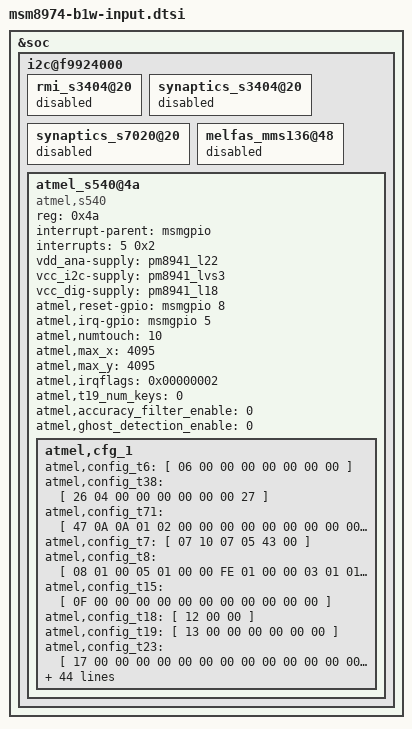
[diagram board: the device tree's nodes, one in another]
/* Copyright (c) 2012, Code Aurora Forum. All rights reserved.
 *
 * This program is free software; you can redistribute it and/or modify
 * it under the terms of the GNU General Public License version 2 and
 * only version 2 as published by the Free Software Foundation.
 *
 * This program is distributed in the hope that it will be useful,
 * but WITHOUT ANY WARRANTY; without even the implied warranty of
 * MERCHANTABILITY or FITNESS FOR A PARTICULAR PURPOSE.  See the
 * GNU General Public License for more details.
 */

&soc {

	i2c@f9924000 {
		rmi_s3404@20  {
			status = "disable";
		};
		synaptics_s3404@20 {
			status = "disable";
		};
		synaptics_s7020@20 {
			status = "disable";
		};
		melfas_mms136@48 {
			status = "disable";
		};
		atmel_s540@4a {
			compatible = "atmel,s540";
			status = "ok";
			reg = <0x4a>;
			interrupt-parent = <&msmgpio>;
			interrupts = <5 0x2>;
			vdd_ana-supply = <&pm8941_l22>;
			vcc_i2c-supply = <&pm8941_lvs3>;
			vcc_dig-supply = <&pm8941_l18>;
			atmel,reset-gpio = <&msmgpio 8 0x00>;
			atmel,irq-gpio = <&msmgpio 5 0x00>;
			atmel,numtouch = <10>;
			atmel,max_x = <4095>;
			atmel,max_y = <4095>;
			atmel,irqflags = <0x00000002>;
			atmel,t19_num_keys = <0>;
			atmel,accuracy_filter_enable = <0>;
			atmel,ghost_detection_enable = <0>;
			/* B1_540S_config_0207_v5.0_F5_#3.xcfg ==> T7 IDLEACQINT 0x20-->0x10 */
			atmel,cfg_1 {
				atmel,config_t6 = [	06			/* 	[GEN_COMMANDPROCESSOR_T6 INSTANCE 0]	 */
					00 00 00 00 00 00 00		];	/* 	0 RESET, 1 BACKUP, 2 CAL, 3 REPORT, 4 Reserved, 5 DIAG, 6 Reserved	 */
				atmel,config_t38 = [	26			/* 	[SPT_USERDATA_T38 INSTANCE 0]	 */
					04			/* 	0 1 DATA[0]	 */
					00			/* 	1 1 DATA[1]	 */
					00			/* 	2 1 DATA[2]	 */
					00			/* 	3 1 DATA[3]	 */
					00			/* 	4 1 DATA[4]	 */
					00			/* 	5 1 DATA[5]	 */
					00			/* 	6 1 DATA[6]	 */
					27		];	/* 	7 1 DATA[7]	 */
				atmel,config_t71 = [	47			/* 	[SPT_DYNAMICCONFIGURATIONCONTAINER_T71 INSTANCE 0]	 */
					0A			/* 	0 1 DATA[0]	 */
					0A			/* 	1 1 DATA[1]	 */
					01			/* 	2 1 DATA[2]	 */
					02			/* 	3 1 DATA[3]	 */
					00			/* 	4 1 DATA[4]	 */
					00			/* 	5 1 DATA[5]	 */
					00			/* 	6 1 DATA[6]	 */
					00			/* 	7 1 DATA[7]	 */
					00			/* 	8 1 DATA[8]	 */
					00			/* 	9 1 DATA[9]	 */
					00			/* 	10 1 DATA[10]	 */
					00			/* 	11 1 DATA[11]	 */
					00			/* 	12 1 DATA[12]	 */
					00			/* 	13 1 DATA[13]	 */
					00			/* 	14 1 DATA[14]	 */
					00			/* 	15 1 DATA[15]	 */
					00			/* 	16 1 DATA[16]	 */
					00			/* 	17 1 DATA[17]	 */
					00			/* 	18 1 DATA[18]	 */
					00			/* 	19 1 DATA[19]	 */
					00			/* 	20 1 DATA[20]	 */
					00			/* 	21 1 DATA[21]	 */
					00			/* 	22 1 DATA[22]	 */
					00			/* 	23 1 DATA[23]	 */
					00			/* 	24 1 DATA[24]	 */
					00			/* 	25 1 DATA[25]	 */
					00			/* 	26 1 DATA[26]	 */
					00			/* 	27 1 DATA[27]	 */
					00			/* 	28 1 DATA[28]	 */
					00			/* 	29 1 DATA[29]	 */
					00			/* 	30 1 DATA[30]	 */
					00			/* 	31 1 DATA[31]	 */
					00			/* 	32 1 DATA[32]	 */
					00			/* 	33 1 DATA[33]	 */
					00			/* 	34 1 DATA[34]	 */
					00			/* 	35 1 DATA[35]	 */
					00			/* 	36 1 DATA[36]	 */
					00			/* 	37 1 DATA[37]	 */
					00			/* 	38 1 DATA[38]	 */
					00			/* 	39 1 DATA[39]	 */
					00			/* 	40 1 DATA[40]	 */
					00			/* 	41 1 DATA[41]	 */
					00			/* 	42 1 DATA[42]	 */
					00			/* 	43 1 DATA[43]	 */
					00			/* 	44 1 DATA[44]	 */
					00			/* 	45 1 DATA[45]	 */
					00			/* 	46 1 DATA[46]	 */
					00			/* 	47 1 DATA[47]	 */
					00			/* 	48 1 DATA[48]	 */
					00			/* 	49 1 DATA[49]	 */
					00			/* 	50 1 DATA[50]	 */
					00			/* 	51 1 DATA[51]	 */
					00			/* 	52 1 DATA[52]	 */
					00			/* 	53 1 DATA[53]	 */
					00			/* 	54 1 DATA[54]	 */
					00			/* 	55 1 DATA[55]	 */
					00			/* 	56 1 DATA[56]	 */
					00			/* 	57 1 DATA[57]	 */
					00			/* 	58 1 DATA[58]	 */
					00			/* 	59 1 DATA[59]	 */
					00			/* 	60 1 DATA[60]	 */
					00			/* 	61 1 DATA[61]	 */
					00			/* 	62 1 DATA[62]	 */
					00			/* 	63 1 DATA[63]	 */
					00			/* 	64 1 DATA[64]	 */
					00			/* 	65 1 DATA[65]	 */
					00			/* 	66 1 DATA[66]	 */
					00			/* 	67 1 DATA[67]	 */
					00			/* 	68 1 DATA[68]	 */
					00			/* 	69 1 DATA[69]	 */
					00			/* 	70 1 DATA[70]	 */
					00			/* 	71 1 DATA[71]	 */
					00			/* 	72 1 DATA[72]	 */
					00			/* 	73 1 DATA[73]	 */
					00			/* 	74 1 DATA[74]	 */
					00			/* 	75 1 DATA[75]	 */
					00			/* 	76 1 DATA[76]	 */
					00			/* 	77 1 DATA[77]	 */
					00			/* 	78 1 DATA[78]	 */
					00			/* 	79 1 DATA[79]	 */
					00			/* 	80 1 DATA[80]	 */
					00			/* 	81 1 DATA[81]	 */
					00			/* 	82 1 DATA[82]	 */
					00			/* 	83 1 DATA[83]	 */
					00			/* 	84 1 DATA[84]	 */
					00			/* 	85 1 DATA[85]	 */
					00			/* 	86 1 DATA[86]	 */
					00			/* 	87 1 DATA[87]	 */
					00			/* 	88 1 DATA[88]	 */
					00			/* 	89 1 DATA[89]	 */
					00			/* 	90 1 DATA[90]	 */
					00			/* 	91 1 DATA[91]	 */
					00			/* 	92 1 DATA[92]	 */
					00			/* 	93 1 DATA[93]	 */
					00			/* 	94 1 DATA[94]	 */
					00			/* 	95 1 DATA[95]	 */
					00			/* 	96 1 DATA[96]	 */
					00			/* 	97 1 DATA[97]	 */
					00			/* 	98 1 DATA[98]	 */
					00			/* 	99 1 DATA[99]	 */
					00			/* 	100 1 DATA[100]	 */
					00			/* 	101 1 DATA[101]	 */
					00			/* 	102 1 DATA[102]	 */
					00			/* 	103 1 DATA[103]	 */
					00			/* 	104 1 DATA[104]	 */
					00			/* 	105 1 DATA[105]	 */
					00			/* 	106 1 DATA[106]	 */
					00			/* 	107 1 DATA[107]	 */
					00			/* 	108 1 DATA[108]	 */
					00			/* 	109 1 DATA[109]	 */
					00			/* 	110 1 DATA[110]	 */
					00		];	/* 	111 1 DATA[111]	 */
				atmel,config_t7 = [	07			/* 	[GEN_POWERCONFIG_T7 INSTANCE 0]	 */
					10			/* 	0 1 IDLEACQINT	 */
					07			/* 	1 1 ACTVACQINT	 */
					05			/* 	2 1 ACTV2IDLETO	 */
					43			/* 	3 1 CFG	 */
					00		];	/* 	4 1 CFG2	 */
				atmel,config_t8 = [	08			/* 	[GEN_ACQUISITIONCONFIG_T8 INSTANCE 0]	 */
					01			/* 	0 1 CHRGTIME	 */
					00			/* 	1 1 ATCHDRIFT	 */
					05			/* 	2 1 TCHDRIFT	 */
					01			/* 	3 1 DRIFTST	 */
					00			/* 	4 1 TCHAUTOCAL	 */
					00			/* 	5 1 SYNC	 */
					FE			/* 	6 1 ATCHCALST	 */
					01			/* 	7 1 ATCHCALSTHR	 */
					00			/* 	8 1 ATCHFRCCALTHR	 */
					00			/* 	9 1 ATCHFRCCALRATIO	 */
					03			/* 	10 1 MEASALLOW	 */
					01			/* 	11 1 MEASIDLEDEF	 */
					01			/* 	12 1 MEASACTVDEF	 */
					00			/* 	13 1 REFMODE	 */
					00		];	/* 	14 1 CFG	 */
				atmel,config_t15 = [	0F			/* 	[TOUCH_KEYARRAY_T15 INSTANCE 0]	 */
					00			/* 	0 1 CTRL	 */
					00			/* 	1 1 XORIGIN	 */
					00			/* 	2 1 YORIGIN	 */
					00			/* 	3 1 XSIZE	 */
					00			/* 	4 1 YSIZE	 */
					00			/* 	5 1 AKSCFG	 */
					00			/* 	6 1 BLEN	 */
					00			/* 	7 1 TCHTHR	 */
					00			/* 	8 1 TCHDI	 */
					00			/* 	9 1 TCHHYST	 */
					00		];	/* 	10 1 RESERVED[0]	 */
				atmel,config_t18 = [	12			/* 	[SPT_COMMSCONFIG_T18 INSTANCE 0]	 */
					00			/* 	0 1 CTRL	 */
					00		];	/* 	1 1 COMMAND	 */
				atmel,config_t19 = [	13			/* 	[SPT_GPIOPWM_T19 INSTANCE 0]	 */
					00			/* 	0 1 CTRL	 */
					00			/* 	1 1 REPORTMASK	 */
					00			/* 	2 1 DIR	 */
					00			/* 	3 1 INTPULLUP	 */
					00			/* 	4 1 OUT	 */
					00		];	/* 	5 1 WAKE	 */
				atmel,config_t23 = [	17			/* 	[TOUCH_PROXIMITY_T23 INSTANCE 0]	 */
					00			/* 	0 1 CTRL	 */
					00			/* 	1 1 XORIGIN	 */
					00			/* 	2 1 YORIGIN	 */
					00			/* 	3 1 XSIZE	 */
					00			/* 	4 1 YSIZE	 */
					00			/* 	5 1 RESERVED[0]	 */
					00			/* 	6 1 BLEN	 */
					00	00		/* 	7 2 FXDDTHR	 */
					00			/* 	9 1 FXDDI	 */
					00			/* 	10 1 AVERAGE	 */
					00	00		/* 	11 2 MVNULLRATE	 */
					00	00		/* 	13 2 MVDTHR	 */
					00		];	/* 	15 1 CFG	 */
				atmel,config_t24 = [	18			/* 	[PROCI_ONETOUCHGESTUREPROCESSOR_T24 INSTANCE 0]	 */
					02			/* 	0 1 CTRL	 */
					01			/* 	1 1 NUMGEST	 */
					08	00		/* 	2 2 GESTEN	 */
					08			/* 	4 1 PROCESS	 */
					7F			/* 	5 1 TAPTO	 */
					00			/* 	6 1 FLICKTO	 */
					00			/* 	7 1 DRAGTO	 */
					00			/* 	8 1 SPRESSTO	 */
					00			/* 	9 1 LPRESSTO	 */
					00			/* 	10 1 REPPRESSTO	 */
					00	00		/* 	11 2 FLICKTHR	 */
					00	00		/* 	13 2 DRAGTHR	 */
					D8	00		/* 	15 2 TAPTHR	 */
					00	00	];	/* 	17 2 THROWTHR	 */
				atmel,config_t25 = [	19			/* 	[SPT_SELFTEST_T25 INSTANCE 0]	 */
					03			/* 	0 1 CTRL	 */
					00			/* 	1 1 CMD	 */
					30	75		/* 	2 2 SIGLIM[0].UPSIGLIM	 */
					F0	55		/* 	4 2 SIGLIM[0].LOSIGLIM	 */
					30	75		/* 	6 2 SIGLIM[1].UPSIGLIM	 */
					F0	55		/* 	8 2 SIGLIM[1].LOSIGLIM	 */
					30	75		/* 	10 2 SIGLIM[2].UPSIGLIM	 */
					F0	55		/* 	12 2 SIGLIM[2].LOSIGLIM	 */
					C8			/* 	14 1 PINDWELLUS	 */
					A0	0F		/* 	15 2 SIGRANGELIM[0]	 */
					A0	0F		/* 	17 2 SIGRANGELIM[1]	 */
					A0	0F	];	/* 	19 2 SIGRANGELIM[2]	 */
				atmel,config_t40 = [	28			/* 	[PROCI_GRIPSUPPRESSION_T40 INSTANCE 0]	 */
					00			/* 	0 1 CTRL	 */
					28			/* 	1 1 XLOGRIP	 */
					28			/* 	2 1 XHIGRIP	 */
					28			/* 	3 1 YLOGRIP	 */
					28		];	/* 	4 1 YHIGRIP	 */
				atmel,config_t42 = [	2A			/* 	[PROCI_TOUCHSUPPRESSION_T42 INSTANCE 0]	 */
					03			/* 	0 1 CTRL	 */
					01			/* 	1 1 APPRTHR	 */
					28			/* 	2 1 MAXAPPRAREA	 */
					2D			/* 	3 1 MAXTCHAREA	 */
					FF			/* 	4 1 SUPSTRENGTH	 */
					00			/* 	5 1 SUPEXTTO	 */
					00			/* 	6 1 MAXNUMTCHS	 */
					19			/* 	7 1 SHAPESTRENGTH	 */
					00			/* 	8 1 SUPDIST	 */
					00			/* 	9 1 DISTHYST	 */
					00			/* 	10 1 MAXSCRNAREA	 */
					04			/* 	11 1 CFG	 */
					00		];	/* 	12 1 UNKNOWN[12]	 */
				atmel,config_t46 = [	2E			/* 	[SPT_CTECONFIG_T46 INSTANCE 0]	 */
					04			/* 	0 1 CTRL	 */
					00			/* 	1 1 MODE	 */
					08			/* 	2 1 IDLESYNCSPERX	 */
					08			/* 	3 1 ACTVSYNCSPERX	 */
					00			/* 	4 1 ADCSPERSYNC	 */
					01			/* 	5 1 PULSESPERADC	 */
					04			/* 	6 1 XSLEW	 */
					00	00		/* 	7 2 SYNCDELAY	 */
					01		];	/* 	9 1 XVOLTAGE	 */
				atmel,config_t47 = [	2F			/* 	[PROCI_STYLUS_T47 INSTANCE 0]	 */
					19			/* 	0 1 CTRL	 */
					00			/* 	1 1 CONTMIN	 */
					FF			/* 	2 1 CONTMAX	 */
					FE			/* 	3 1 STABILITY	 */
					05			/* 	4 1 MAXTCHAREA	 */
					1E			/* 	5 1 AMPLTHR	 */
					0F			/* 	6 1 STYSHAPE	 */
					96			/* 	7 1 HOVERSUP	 */
					03			/* 	8 1 CONFTHR	 */
					10			/* 	9 1 SYNCSPERX	 */
					E0			/* 	10 1 XPOSADJ	 */
					E0			/* 	11 1 YPOSADJ	 */
					03			/* 	12 1 CFG	 */
					00			/* 	13 1 RESERVED[0]	 */
					00			/* 	14 1 RESERVED[1]	 */
					00			/* 	15 1 RESERVED[2]	 */
					00			/* 	16 1 RESERVED[3]	 */
					00			/* 	17 1 RESERVED[4]	 */
					00			/* 	18 1 RESERVED[5]	 */
					00			/* 	19 1 RESERVED[6]	 */
					00			/* 	20 1 SUPSTYTO	 */
					00			/* 	21 1 MAXNUMSTY	 */
					8E			/* 	22 1 XEDGECTRL	 */
					2A			/* 	23 1 XEDGEDIST	 */
					82			/* 	24 1 YEDGECTRL	 */
					2D		];	/* 	25 1 YEDGEDIST	 */
				atmel,config_t55 = [	37			/* 	[PROCI_ADAPTIVETHRESHOLD_T55 INSTANCE 0]	 */
					00			/* 	0 1 CTRL	 */
					00			/* 	1 1 TARGETTHR	 */
					00			/* 	2 1 THRADJLIM	 */
					00			/* 	3 1 RESETSTEPTIME	 */
					00			/* 	4 1 FORCECHGDIST	 */
					00			/* 	5 1 FORCECHGTIME	 */
					00		];	/* 	6 1 LOWESTTHR	 */
				atmel,config_t56 = [	38			/* 	[PROCI_SHIELDLESS_T56 INSTANCE 0]	 */
					01			/* 	0 1 CTRL	 */
					00			/* 	1 1 COMMAND	 */
					01			/* 	2 1 OPTINT	 */
					3D			/* 	3 1 INTTIME	 */
					06			/* 	4 1 INTDELAY[0]	 */
					06			/* 	5 1 INTDELAY[1]	 */
					06			/* 	6 1 INTDELAY[2]	 */
					06			/* 	7 1 INTDELAY[3]	 */
					06			/* 	8 1 INTDELAY[4]	 */
					06			/* 	9 1 INTDELAY[5]	 */
					06			/* 	10 1 INTDELAY[6]	 */
					06			/* 	11 1 INTDELAY[7]	 */
					06			/* 	12 1 INTDELAY[8]	 */
					06			/* 	13 1 INTDELAY[9]	 */
					06			/* 	14 1 INTDELAY[10]	 */
					06			/* 	15 1 INTDELAY[11]	 */
					06			/* 	16 1 INTDELAY[12]	 */
					06			/* 	17 1 INTDELAY[13]	 */
					06			/* 	18 1 INTDELAY[14]	 */
					06			/* 	19 1 INTDELAY[15]	 */
					08			/* 	20 1 INTDELAY[16]	 */
					08			/* 	21 1 INTDELAY[17]	 */
					08			/* 	22 1 INTDELAY[18]	 */
					08			/* 	23 1 INTDELAY[19]	 */
					08			/* 	24 1 INTDELAY[20]	 */
					08			/* 	25 1 INTDELAY[21]	 */
					08			/* 	26 1 INTDELAY[22]	 */
					08			/* 	27 1 INTDELAY[23]	 */
					08			/* 	28 1 INTDELAY[24]	 */
					08			/* 	29 1 INTDELAY[25]	 */
					08			/* 	30 1 INTDELAY[26]	 */
					08			/* 	31 1 INTDELAY[27]	 */
					08			/* 	32 1 INTDELAY[28]	 */
					08			/* 	33 1 INTDELAY[29]	 */
					00			/* 	34 1 MULTICUTGC	 */
					00		];	/* 	35 1 GCLIMIT	 */
				atmel,config_t61 = [	3D			/* 	[SPT_TIMER_T61 INSTANCE 0]	 */
					03			/* 	0 1 CTRL	 */
					00			/* 	1 1 CMD	 */
					00			/* 	2 1 MODE	 */
					64	00		/* 	3 2 PERIOD	 */
								/* 	[SPT_TIMER_T61 INSTANCE 1]	 */
					00			/* 	0 1 CTRL	 */
					00			/* 	1 1 CMD	 */
					00			/* 	2 1 MODE	 */
					00	00	];	/* 	3 2 PERIOD	 */
				atmel,config_t65 = [	41			/* 	[PROCI_LENSBENDING_T65 INSTANCE 0]	 */
					01			/* 	0 1 CTRL	 */
					03			/* 	1 1 GRADTHR	 */
					00	00		/* 	2 2 YLONOISEMUL	 */
					00	00		/* 	4 2 YLONOISEDIV	 */
					00	00		/* 	6 2 YHINOISEMUL	 */
					00	00		/* 	8 2 YHINOISEDIV	 */
					00			/* 	10 1 LPFILTCOEF	 */
					00	00		/* 	11 2 FORCESCALE	 */
					00			/* 	13 1 FORCETHR	 */
					00			/* 	14 1 FORCETHRHYST	 */
					00			/* 	15 1 FORCEDI	 */
					00			/* 	16 1 FORCEHYST	 */
					01			/* 	17 1 ATCHRATIO	 */
					00	00	];	/* 	18 2 TOTVARLIM	 */
				atmel,config_t66 = [	42			/* 	[SPT_GOLDENREFERENCES_T66 INSTANCE 0]	 */
					00			/* 	0 1 CTRL	 */
					00			/* 	1 1 FCALFAILTHR	 */
					00		];	/* 	2 1 FCALDRIFTCNT	 */
				atmel,config_t69 = [	45			/* 	[PROCI_PALMGESTUREPROCESSOR_T69 INSTANCE 0]	 */
					00			/* 	0 1 CTRL	 */
					00			/* 	1 1 LONGDIMTHR	 */
					00			/* 	2 1 SHORTDIMTHR	 */
					00			/* 	3 1 LONGDIMHYST	 */
					00			/* 	4 1 SHORTDIMHYST	 */
					00			/* 	5 1 MOVTHR	 */
					00			/* 	6 1 MOVTHRTO	 */
					00			/* 	7 1 AREATHR	 */
					00		];	/* 	8 1 AREATHRTO	 */
				atmel,config_t70 = [	46			/* 	[SPT_DYNAMICCONFIGURATIONCONTROLLER_T70 INSTANCE 0]	 */
					00			/* 	0 1 CTRL	 */
					00	00		/* 	1 2 EVENT	 */
					00			/* 	3 1 OBJTYPE	 */
					00			/* 	4 1 RESERVED[0]	 */
					00			/* 	5 1 OBJINST	 */
					00			/* 	6 1 DSTOFFSET	 */
					00	00		/* 	7 2 SRCOFFSET	 */
					00			/* 	9 1 LENGTH	 */
								/* 	[SPT_DYNAMICCONFIGURATIONCONTROLLER_T70 INSTANCE 1]	 */
					00			/* 	0 1 CTRL	 */
					00	00		/* 	1 2 EVENT	 */
					00			/* 	3 1 OBJTYPE	 */
					00			/* 	4 1 RESERVED[0]	 */
					00			/* 	5 1 OBJINST	 */
					00			/* 	6 1 DSTOFFSET	 */
					00	00		/* 	7 2 SRCOFFSET	 */
					00			/* 	9 1 LENGTH	 */
								/* 	[SPT_DYNAMICCONFIGURATIONCONTROLLER_T70 INSTANCE 2]	 */
					00			/* 	0 1 CTRL	 */
					00	00		/* 	1 2 EVENT	 */
					00			/* 	3 1 OBJTYPE	 */
					00			/* 	4 1 RESERVED[0]	 */
					00			/* 	5 1 OBJINST	 */
					00			/* 	6 1 DSTOFFSET	 */
					00	00		/* 	7 2 SRCOFFSET	 */
					00			/* 	9 1 LENGTH	 */
								/* 	[SPT_DYNAMICCONFIGURATIONCONTROLLER_T70 INSTANCE 3]	 */
					00			/* 	0 1 CTRL	 */
					00	00		/* 	1 2 EVENT	 */
					00			/* 	3 1 OBJTYPE	 */
					00			/* 	4 1 RESERVED[0]	 */
					00			/* 	5 1 OBJINST	 */
					00			/* 	6 1 DSTOFFSET	 */
					00	00		/* 	7 2 SRCOFFSET	 */
					00			/* 	9 1 LENGTH	 */
								/* 	[SPT_DYNAMICCONFIGURATIONCONTROLLER_T70 INSTANCE 4]	 */
					00			/* 	0 1 CTRL	 */
					00	00		/* 	1 2 EVENT	 */
					00			/* 	3 1 OBJTYPE	 */
					00			/* 	4 1 RESERVED[0]	 */
					00			/* 	5 1 OBJINST	 */
					00			/* 	6 1 DSTOFFSET	 */
					00	00		/* 	7 2 SRCOFFSET	 */
					00			/* 	9 1 LENGTH	 */
								/* 	[SPT_DYNAMICCONFIGURATIONCONTROLLER_T70 INSTANCE 5]	 */
					00			/* 	0 1 CTRL	 */
					00	00		/* 	1 2 EVENT	 */
					00			/* 	3 1 OBJTYPE	 */
					00			/* 	4 1 RESERVED[0]	 */
					00			/* 	5 1 OBJINST	 */
					00			/* 	6 1 DSTOFFSET	 */
					00	00		/* 	7 2 SRCOFFSET	 */
					00			/* 	9 1 LENGTH	 */
								/* 	[SPT_DYNAMICCONFIGURATIONCONTROLLER_T70 INSTANCE 6]	 */
					00			/* 	0 1 CTRL	 */
					00	00		/* 	1 2 EVENT	 */
					00			/* 	3 1 OBJTYPE	 */
					00			/* 	4 1 RESERVED[0]	 */
					00			/* 	5 1 OBJINST	 */
					00			/* 	6 1 DSTOFFSET	 */
					00	00		/* 	7 2 SRCOFFSET	 */
					00			/* 	9 1 LENGTH	 */
								/* 	[SPT_DYNAMICCONFIGURATIONCONTROLLER_T70 INSTANCE 7]	 */
					00			/* 	0 1 CTRL	 */
					00	00		/* 	1 2 EVENT	 */
					00			/* 	3 1 OBJTYPE	 */
					00			/* 	4 1 RESERVED[0]	 */
					00			/* 	5 1 OBJINST	 */
					00			/* 	6 1 DSTOFFSET	 */
					00	00		/* 	7 2 SRCOFFSET	 */
					00		];	/* 	9 1 LENGTH	 */
				atmel,config_t72 = [	48			/* 	[PROCG_NOISESUPPRESSION_T72 INSTANCE 0]	 */
					01			/* 	0 1 CTRL	 */
					00			/* 	1 1 CALCFG1	 */
					00			/* 	2 1 CFG1	 */
					11			/* 	3 1 CFG2	 */
					00			/* 	4 1 DEBUGCFG	 */
					05			/* 	5 1 HOPCNT	 */
					0A			/* 	6 1 HOPCNTPER	 */
					05			/* 	7 1 HOPEVALTO	 */
					05			/* 	8 1 HOPST	 */
					40			/* 	9 1 NLGAINDUALX	 */
					0A			/* 	10 1 MINNLTHR	 */
					0A			/* 	11 1 INCNLTHR	 */
					08			/* 	12 1 FALLNLTHR	 */
					05			/* 	13 1 NLTHRMARGIN	 */
					10			/* 	14 1 MINTHRADJ	 */
					64			/* 	15 1 NLTHRLIMIT	 */
					0D			/* 	16 1 BGSCAN	 */
					60			/* 	17 1 NLGAINSINGX	 */
					78			/* 	18 1 BLKNLTHR	 */
					00			/* 	19 1 CFG3	 */
					00			/* 	20 1 STATE[0]_CTRL	 */
					0E			/* 	21 1 STATE[0]_FREQ[0]	 */
					0F			/* 	22 1 STATE[0]_FREQ[1]	 */
					10			/* 	23 1 STATE[0]_FREQ[2]	 */
					11			/* 	24 1 STATE[0]_FREQ[3]	 */
					12			/* 	25 1 STATE[0]_FREQ[4]	 */
					14			/* 	26 1 STATE[0]_TCHAPX[0]	 */
					14			/* 	27 1 STATE[0]_TCHAPX[1]	 */
					14			/* 	28 1 STATE[0]_TCHAPX[2]	 */
					14			/* 	29 1 STATE[0]_TCHAPX[3]	 */
					14			/* 	30 1 STATE[0]_TCHAPX[4]	 */
					08			/* 	31 1 STATE[0]_NOTCHAPX[0]	 */
					08			/* 	32 1 STATE[0]_NOTCHAPX[1]	 */
					08			/* 	33 1 STATE[0]_NOTCHAPX[2]	 */
					08			/* 	34 1 STATE[0]_NOTCHAPX[3]	 */
					08			/* 	35 1 STATE[0]_NOTCHAPX[4]	 */
					00			/* 	36 1 STATE[0]_PC	 */
					00			/* 	37 1 STATE[0]_LOWNLTHR	 */
					18			/* 	38 1 STATE[0]_HIGHNLTHR	 */
					12			/* 	39 1 STATE[0]_CNT	 */
					01			/* 	40 1 STATE[1]_CTRL	 */
					0E			/* 	41 1 STATE[1]_FREQ[0]	 */
					0F			/* 	42 1 STATE[1]_FREQ[1]	 */
					10			/* 	43 1 STATE[1]_FREQ[2]	 */
					11			/* 	44 1 STATE[1]_FREQ[3]	 */
					12			/* 	45 1 STATE[1]_FREQ[4]	 */
					30			/* 	46 1 STATE[1]_TCHAPX[0]	 */
					30			/* 	47 1 STATE[1]_TCHAPX[1]	 */
					30			/* 	48 1 STATE[1]_TCHAPX[2]	 */
					30			/* 	49 1 STATE[1]_TCHAPX[3]	 */
					30			/* 	50 1 STATE[1]_TCHAPX[4]	 */
					20			/* 	51 1 STATE[1]_NOTCHAPX[0]	 */
					20			/* 	52 1 STATE[1]_NOTCHAPX[1]	 */
					20			/* 	53 1 STATE[1]_NOTCHAPX[2]	 */
					20			/* 	54 1 STATE[1]_NOTCHAPX[3]	 */
					20			/* 	55 1 STATE[1]_NOTCHAPX[4]	 */
					00			/* 	56 1 STATE[1]_PC	 */
					0E			/* 	57 1 STATE[1]_LOWNLTHR	 */
					1E			/* 	58 1 STATE[1]_HIGHNLTHR	 */
					11			/* 	59 1 STATE[1]_CNT	 */
					01			/* 	60 1 STATE[2]_CTRL	 */
					0E			/* 	61 1 STATE[2]_FREQ[0]	 */
					0F			/* 	62 1 STATE[2]_FREQ[1]	 */
					10			/* 	63 1 STATE[2]_FREQ[2]	 */
					11			/* 	64 1 STATE[2]_FREQ[3]	 */
					12			/* 	65 1 STATE[2]_FREQ[4]	 */
					38			/* 	66 1 STATE[2]_TCHAPX[0]	 */
					38			/* 	67 1 STATE[2]_TCHAPX[1]	 */
					38			/* 	68 1 STATE[2]_TCHAPX[2]	 */
					38			/* 	69 1 STATE[2]_TCHAPX[3]	 */
					38			/* 	70 1 STATE[2]_TCHAPX[4]	 */
					20			/* 	71 1 STATE[2]_NOTCHAPX[0]	 */
					20			/* 	72 1 STATE[2]_NOTCHAPX[1]	 */
					20			/* 	73 1 STATE[2]_NOTCHAPX[2]	 */
					20			/* 	74 1 STATE[2]_NOTCHAPX[3]	 */
					20			/* 	75 1 STATE[2]_NOTCHAPX[4]	 */
					00			/* 	76 1 STATE[2]_PC	 */
					0E			/* 	77 1 STATE[2]_LOWNLTHR	 */
					00			/* 	78 1 STATE[2]_HIGHNLTHR	 */
					11			/* 	79 1 STATE[2]_CNT	 */
					0A			/* 	80 1 UNKNOWN[80]	 */
					07			/* 	81 1 UNKNOWN[81]	 */
					64			/* 	82 1 UNKNOWN[82]	 */
					03		];	/* 	83 1 UNKNOWN[83]	 */
				atmel,config_t78 = [	4E			/* 	[PROCI_GLOVEDETECTION_T78 INSTANCE 0]	 */
					00			/* 	0 1 CTRL	 */
					00			/* 	1 1 MINAREA	 */
					00			/* 	2 1 CONFTHR	 */
					00			/* 	3 1 MINDIST	 */
					00			/* 	4 1 GLOVEMODETO	 */
					00			/* 	5 1 SUPTO	 */
					00			/* 	6 1 SYNCSPERX	 */
					00		];	/* 	7 1 HITHRMARGIN	 */
				atmel,config_t80 = [	50			/* 	[PROCI_RETRANSMISSIONCOMPENSATION_T80 INSTANCE 0]	 */
					8D			/* 	0 1 CTRL	 */
					1E			/* 	1 1 COMPGAIN	 */
					78			/* 	2 1 TARGETDELTA	 */
					00			/* 	3 1 COMPTHR	 */
					0A			/* 	4 1 ATCHTHR	 */
					CA			/* 	5 1 MOISTCFG	 */
					00		];	/* 	6 1 MOISTDTO	 */
				atmel,config_t92 = [	5C			/* 	[UNKNOWN_T92 INSTANCE 0]	 */
					00			/* 	0 1 UNKNOWN[0]	 */
					00			/* 	1 1 UNKNOWN[1]	 */
					00			/* 	2 1 UNKNOWN[2]	 */
					00			/* 	3 1 UNKNOWN[3]	 */
					00			/* 	4 1 UNKNOWN[4]	 */
					00			/* 	5 1 UNKNOWN[5]	 */
					00			/* 	6 1 UNKNOWN[6]	 */
					00			/* 	7 1 UNKNOWN[7]	 */
					00			/* 	8 1 UNKNOWN[8]	 */
					00			/* 	9 1 UNKNOWN[9]	 */
					00			/* 	10 1 UNKNOWN[10]	 */
					00			/* 	11 1 UNKNOWN[11]	 */
					00			/* 	12 1 UNKNOWN[12]	 */
					00			/* 	13 1 UNKNOWN[13]	 */
					00			/* 	14 1 UNKNOWN[14]	 */
					00			/* 	15 1 UNKNOWN[15]	 */
					00			/* 	16 1 UNKNOWN[16]	 */
					00			/* 	17 1 UNKNOWN[17]	 */
					00			/* 	18 1 UNKNOWN[18]	 */
					00			/* 	19 1 UNKNOWN[19]	 */
					00			/* 	20 1 UNKNOWN[20]	 */
					00			/* 	21 1 UNKNOWN[21]	 */
					00			/* 	22 1 UNKNOWN[22]	 */
					00			/* 	23 1 UNKNOWN[23]	 */
					00			/* 	24 1 UNKNOWN[24]	 */
					00			/* 	25 1 UNKNOWN[25]	 */
					00			/* 	26 1 UNKNOWN[26]	 */
					00			/* 	27 1 UNKNOWN[27]	 */
					00			/* 	28 1 UNKNOWN[28]	 */
					00			/* 	29 1 UNKNOWN[29]	 */
					00			/* 	30 1 UNKNOWN[30]	 */
					00			/* 	31 1 UNKNOWN[31]	 */
					00			/* 	32 1 UNKNOWN[32]	 */
					00			/* 	33 1 UNKNOWN[33]	 */
					00			/* 	34 1 UNKNOWN[34]	 */
					00			/* 	35 1 UNKNOWN[35]	 */
					00			/* 	36 1 UNKNOWN[36]	 */
					00			/* 	37 1 UNKNOWN[37]	 */
					00			/* 	38 1 UNKNOWN[38]	 */
					00			/* 	39 1 UNKNOWN[39]	 */
					00			/* 	40 1 UNKNOWN[40]	 */
					00			/* 	41 1 UNKNOWN[41]	 */
					00			/* 	42 1 UNKNOWN[42]	 */
					00			/* 	43 1 UNKNOWN[43]	 */
					00			/* 	44 1 UNKNOWN[44]	 */
					00			/* 	45 1 UNKNOWN[45]	 */
					00			/* 	46 1 UNKNOWN[46]	 */
					00			/* 	47 1 UNKNOWN[47]	 */
					00			/* 	48 1 UNKNOWN[48]	 */
					00			/* 	49 1 UNKNOWN[49]	 */
					00			/* 	50 1 UNKNOWN[50]	 */
					00			/* 	51 1 UNKNOWN[51]	 */
					00			/* 	52 1 UNKNOWN[52]	 */
					00			/* 	53 1 UNKNOWN[53]	 */
					00			/* 	54 1 UNKNOWN[54]	 */
					00			/* 	55 1 UNKNOWN[55]	 */
					00			/* 	56 1 UNKNOWN[56]	 */
					00			/* 	57 1 UNKNOWN[57]	 */
					00			/* 	58 1 UNKNOWN[58]	 */
					00			/* 	59 1 UNKNOWN[59]	 */
					00			/* 	60 1 UNKNOWN[60]	 */
					00			/* 	61 1 UNKNOWN[61]	 */
					00			/* 	62 1 UNKNOWN[62]	 */
					00			/* 	63 1 UNKNOWN[63]	 */
					00			/* 	64 1 UNKNOWN[64]	 */
					00			/* 	65 1 UNKNOWN[65]	 */
					00			/* 	66 1 UNKNOWN[66]	 */
					00			/* 	67 1 UNKNOWN[67]	 */
					00			/* 	68 1 UNKNOWN[68]	 */
					00			/* 	69 1 UNKNOWN[69]	 */
					00			/* 	70 1 UNKNOWN[70]	 */
					00			/* 	71 1 UNKNOWN[71]	 */
					00			/* 	72 1 UNKNOWN[72]	 */
					00			/* 	73 1 UNKNOWN[73]	 */
					00			/* 	74 1 UNKNOWN[74]	 */
					00			/* 	75 1 UNKNOWN[75]	 */
					00			/* 	76 1 UNKNOWN[76]	 */
					00			/* 	77 1 UNKNOWN[77]	 */
					00			/* 	78 1 UNKNOWN[78]	 */
					00			/* 	79 1 UNKNOWN[79]	 */
					00			/* 	80 1 UNKNOWN[80]	 */
					00			/* 	81 1 UNKNOWN[81]	 */
					00			/* 	82 1 UNKNOWN[82]	 */
					00			/* 	83 1 UNKNOWN[83]	 */
					00			/* 	84 1 UNKNOWN[84]	 */
					00			/* 	85 1 UNKNOWN[85]	 */
					00			/* 	86 1 UNKNOWN[86]	 */
					00			/* 	87 1 UNKNOWN[87]	 */
					00			/* 	88 1 UNKNOWN[88]	 */
					00		];	/* 	89 1 UNKNOWN[89]	 */
				atmel,config_t93 = [	5D			/* 	[UNKNOWN_T93 INSTANCE 0]	 */
					01			/* 	0 1 UNKNOWN[0]	 */
					2B			/* 	1 1 UNKNOWN[1]	 */
					00			/* 	2 1 UNKNOWN[2]	 */
					0D			/* 	3 1 UNKNOWN[3]	 */
					04			/* 	4 1 UNKNOWN[4]	 */
					2B			/* 	5 1 UNKNOWN[5]	 */
					00			/* 	6 1 UNKNOWN[6]	 */
					56			/* 	7 1 UNKNOWN[7]	 */
					07			/* 	8 1 UNKNOWN[8]	 */
					90			/* 	9 1 UNKNOWN[9]	 */
					00			/* 	10 1 UNKNOWN[10]	 */
					00			/* 	11 1 UNKNOWN[11]	 */
					18			/* 	12 1 UNKNOWN[12]	 */
					00			/* 	13 1 UNKNOWN[13]	 */
					41			/* 	14 1 UNKNOWN[14]	 */
					00			/* 	15 1 UNKNOWN[15]	 */
					2C			/* 	16 1 UNKNOWN[16]	 */
					00		];	/* 	17 1 UNKNOWN[17]	 */
				atmel,config_t100 = [	64			/* 	[TOUCH_MULTITOUCHSCREEN_T100 INSTANCE 0]	 */
					83			/* 	0 1 CTRL	 */
					3C			/* 	1 1 CFG1	 */
					0F			/* 	2 1 SCRAUX	 */
					0E			/* 	3 1 TCHAUX	 */
					00			/* 	4 1 TCHEVENTCFG	 */
					00			/* 	5 1 AKSCFG	 */
					0A			/* 	6 1 NUMTCH	 */
					08			/* 	7 1 XYCFG	 */
					00			/* 	8 1 XORIGIN	 */
					1E			/* 	9 1 XSIZE	 */
					2D			/* 	10 1 XPITCH	 */
					05			/* 	11 1 XLOCLIP	 */
					05			/* 	12 1 XHICLIP	 */
					FF	0E		/* 	13 2 XRANGE	 */
					0C			/* 	15 1 XEDGECFG	 */
					25			/* 	16 1 XEDGEDIST	 */
					00			/* 	17 1 DXXEDGECFG	 */
					00			/* 	18 1 DXXEDGEDIST	 */
					00			/* 	19 1 YORIGIN	 */
					11			/* 	20 1 YSIZE	 */
					2D			/* 	21 1 YPITCH	 */
					02			/* 	22 1 YLOCLIP	 */
					02			/* 	23 1 YHICLIP	 */
					6F	08		/* 	24 2 YRANGE	 */
					00			/* 	26 1 YEDGECFG	 */
					00			/* 	27 1 YEDGEDIST	 */
					06			/* 	28 1 GAIN	 */
					03			/* 	29 1 DXGAIN	 */
					4B			/* 	30 1 TCHTHR	 */
					15			/* 	31 1 TCHHYST	 */
					1C			/* 	32 1 INTTHR	 */
					00			/* 	33 1 NOISESF	 */
					00			/* 	34 1 CUTOFFTHR	 */
					46			/* 	35 1 MRGTHR	 */
					FF			/* 	36 1 MRGTHRADJSTR	 */
					1E			/* 	37 1 MRGHYST	 */
					00			/* 	38 1 DXTHRSF	 */
					01			/* 	39 1 TCHDIDOWN	 */
					02			/* 	40 1 TCHDIUP	 */
					00			/* 	41 1 NEXTTCHDI	 */
					43			/* 	42 1 RESERVED[0]	 */
					2D			/* 	43 1 JUMPLIMIT	 */
					04			/* 	44 1 MOVFILTER	 */
					C8			/* 	45 1 MOVSMOOTH	 */
					30			/* 	46 1 MOVPRED	 */
					0A	00		/* 	47 2 MOVHYSTI	 */
					04	00		/* 	49 2 MOVHYSTN	 */
					00			/* 	51 1 AMPLHYST	 */
					01			/* 	52 1 SCRAREAHYST	 */
					05		];	/* 	53 1 INTTHRHYST	 */
				atmel,config_t101 = [	65			/* 	[SPT_TOUCHSCREENHOVER_T101 INSTANCE 0]	 */
					00			/* 	0 1 CTRL	 */
					00			/* 	1 1 XLOCLIP	 */
					00			/* 	2 1 XHICLIP	 */
					00			/* 	3 1 XEDGECFG	 */
					00			/* 	4 1 XEDGEDIST	 */
					00			/* 	5 1 XGAIN	 */
					00			/* 	6 1 XHVRTHR	 */
					00			/* 	7 1 XHVRHYST	 */
					00			/* 	8 1 YLOCLIP	 */
					00			/* 	9 1 YHICLIP	 */
					00			/* 	10 1 YEDGECFG	 */
					00			/* 	11 1 YEDGEDIST	 */
					00			/* 	12 1 YGAIN	 */
					00			/* 	13 1 YHVRTHR	 */
					00			/* 	14 1 YHVRHYST	 */
					00			/* 	15 1 HVRDI	 */
					00			/* 	16 1 CONFTHR	 */
					00			/* 	17 1 MOVFILTER	 */
					00			/* 	18 1 MOVSMOOTH	 */
					00			/* 	19 1 MOVPRED	 */
					00	00		/* 	20 2 MOVHYSTI	 */
					00	00		/* 	22 2 MOVHYSTN	 */
					00		];	/* 	24 1 HVRAUX	 */
				atmel,config_t102 = [	66			/* 	[SPT_SELFCAPCBCRCONFIG_T102 INSTANCE 0]	 */
					02			/* 	0 1 CTRL	 */
					00			/* 	1 1 CMD	 */
					00			/* 	2 1 MODE	 */
					E8	03		/* 	3 2 TUNTHR	 */
					80	02		/* 	5 2 TUNHYST	 */
					01			/* 	7 1 TUNAVGCYCLES	 */
					46			/* 	8 1 TUNCFG	 */
					00			/* 	9 1 TUNSYNCSPERL	 */
					01			/* 	10 1 TUNGAIN	 */
					00			/* 	11 1 BGTUNCTRL	 */
					2D			/* 	12 1 PRECHRGTIME	 */
					50			/* 	13 1 CHRGTIME	 */
					2D			/* 	14 1 INTTIME	 */
					00			/* 	15 1 RESERVED[0]	 */
					00			/* 	16 1 RESERVED[1]	 */
					00			/* 	17 1 RESERVED[2]	 */
					10			/* 	18 1 IDLESYNCSPERL	 */
					10			/* 	19 1 ACTVSYNCSPERL	 */
					0A			/* 	20 1 DRIFT	 */
					03			/* 	21 1 DRIFTST	 */
					00			/* 	22 1 DRIFTSTHRSF	 */
					09			/* 	23 1 FILTER	 */
					02			/* 	24 1 FILTCFG	 */
					00			/* 	25 1 DYNIIRTHRU	 */
					00			/* 	26 1 DYNIIRTHRL	 */
					00			/* 	27 1 DYNIIRCLMP	 */
					4A		];	/* 	28 1 RECALCFG	 */
				atmel,config_t103 = [	67			/* 	[UNKNOWN_T103 INSTANCE 0]	 */
					00			/* 	0 1 UNKNOWN[0]	 */
					00			/* 	1 1 UNKNOWN[1]	 */
					00			/* 	2 1 UNKNOWN[2]	 */
					00			/* 	3 1 UNKNOWN[3]	 */
					00			/* 	4 1 UNKNOWN[4]	 */
					00			/* 	5 1 UNKNOWN[5]	 */
					00			/* 	6 1 UNKNOWN[6]	 */
					00			/* 	7 1 UNKNOWN[7]	 */
					00			/* 	8 1 UNKNOWN[8]	 */
					00			/* 	9 1 UNKNOWN[9]	 */
					00			/* 	10 1 UNKNOWN[10]	 */
					00			/* 	11 1 UNKNOWN[11]	 */
					00			/* 	12 1 UNKNOWN[12]	 */
					00			/* 	13 1 UNKNOWN[13]	 */
								/* 	[UNKNOWN_T103 INSTANCE 1]	 */
					00			/* 	0 1 UNKNOWN[0]	 */
					00			/* 	1 1 UNKNOWN[1]	 */
					00			/* 	2 1 UNKNOWN[2]	 */
					00			/* 	3 1 UNKNOWN[3]	 */
					00			/* 	4 1 UNKNOWN[4]	 */
					00			/* 	5 1 UNKNOWN[5]	 */
					00			/* 	6 1 UNKNOWN[6]	 */
					00			/* 	7 1 UNKNOWN[7]	 */
					00			/* 	8 1 UNKNOWN[8]	 */
					00			/* 	9 1 UNKNOWN[9]	 */
					00			/* 	10 1 UNKNOWN[10]	 */
					00			/* 	11 1 UNKNOWN[11]	 */
					00			/* 	12 1 UNKNOWN[12]	 */
					00		];	/* 	13 1 UNKNOWN[13]	 */
				atmel,config_t104 = [	68			/* 	[SPT_AUXTOUCHCONFIG_T104 INSTANCE 0]	 */
					01			/* 	0 1 CTRL	 */
					03			/* 	1 1 XGAIN	 */
					46			/* 	2 1 XTCHTHR	 */
					00			/* 	3 1 XTCHHYST	 */
					05			/* 	4 1 XINTTHR	 */
					00			/* 	5 1 XINTHYST	 */
					03			/* 	6 1 YGAIN	 */
					46			/* 	7 1 YTCHTHR	 */
					00			/* 	8 1 YTCHHYST	 */
					05			/* 	9 1 YINTTHR	 */
					00		];	/* 	10 1 YINTHYST	 */
				atmel,config_t105 = [	69			/* 	[SPT_DRIVENPLATEHOVERCONFIG_T105 INSTANCE 0]	 */
					00			/* 	0 1 CTRL	 */
					00			/* 	1 1 MODE	 */
					00			/* 	2 1 PRECHRGTIME	 */
					00			/* 	3 1 CHRGTIME	 */
					00			/* 	4 1 INTTIME	 */
					00			/* 	5 1 RESERVED[0]	 */
					00			/* 	6 1 RESERVED[1]	 */
					00			/* 	7 1 RESERVED[2]	 */
					00			/* 	8 1 IDLESYNCSPERL	 */
					00			/* 	9 1 ACTVSYNCSPERL	 */
					00			/* 	10 1 DRIFT	 */
					00			/* 	11 1 DRIFTST	 */
					00			/* 	12 1 DRIFTSTHRSF	 */
					00			/* 	13 1 FILTER	 */
					00			/* 	14 1 FILTCFG	 */
					00			/* 	15 1 DYNIIRTHRU	 */
					00			/* 	16 1 DYNIIRTHRL	 */
					00		];	/* 	17 1 DYNIIRCLMP	 */
			};
		};
	};

};
